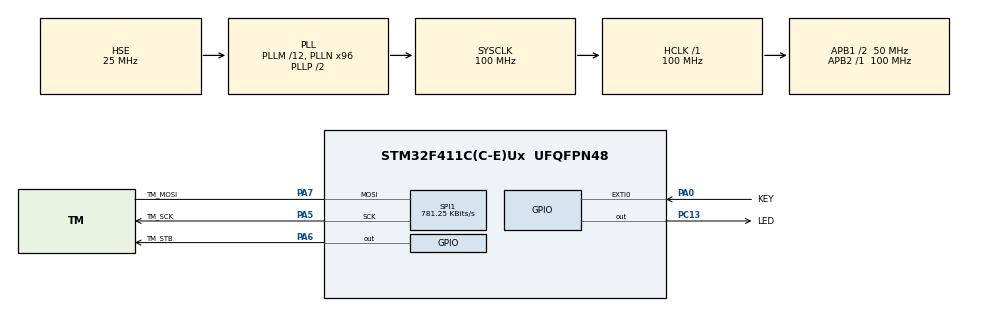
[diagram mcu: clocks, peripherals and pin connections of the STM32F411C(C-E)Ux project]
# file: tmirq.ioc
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Mcu.Family=STM32F4
Mcu.Name=STM32F411C(C-E)Ux
Mcu.Package=UFQFPN48
NVIC.EXTI0_IRQn=true\:0\:0\:false\:false\:true\:true\:true\:true
NVIC.PriorityGroup=NVIC_PRIORITYGROUP_4
NVIC.TIM1_BRK_TIM9_IRQn=true\:15\:0\:false\:false\:true\:false\:true\:true
NVIC.TimeBase=TIM1_BRK_TIM9_IRQn
NVIC.TimeBaseIP=TIM9
PA0-WKUP.GPIO_Label=KEY
PA0-WKUP.GPIO_ModeDefaultEXTI=GPIO_MODE_IT_RISING_FALLING
PA0-WKUP.GPIO_PuPd=GPIO_PULLUP
PA0-WKUP.Signal=GPXTI0
PA13.Mode=Serial_Wire
PA13.Signal=SYS_JTMS-SWDIO
PA14.Mode=Serial_Wire
PA14.Signal=SYS_JTCK-SWCLK
PA5.GPIO_Label=TM_SCK
PA5.Mode=Simplex_Bidirectional_Master
PA5.Signal=SPI1_SCK
PA6.GPIO_Label=TM_STB
PA6.GPIO_PuPd=GPIO_PULLUP
PA6.GPIO_Speed=GPIO_SPEED_FREQ_VERY_HIGH
PA6.PinState=GPIO_PIN_SET
PA6.Signal=GPIO_Output
PA7.GPIO_Label=TM_MOSI
PA7.Mode=Simplex_Bidirectional_Master
PA7.Signal=SPI1_MOSI
PC13-ANTI_TAMP.GPIO_Label=LED
PC13-ANTI_TAMP.GPIO_PuPd=GPIO_PULLUP
PC13-ANTI_TAMP.PinState=GPIO_PIN_SET
PC13-ANTI_TAMP.Signal=GPIO_Output
PH0\ -\ OSC_IN.Mode=HSE-External-Oscillator
PH0\ -\ OSC_IN.Signal=RCC_OSC_IN
PH1\ -\ OSC_OUT.Mode=HSE-External-Oscillator
PH1\ -\ OSC_OUT.Signal=RCC_OSC_OUT
ProjectManager.HeapSize=0x200
ProjectManager.StackSize=0x400
ProjectManager.TargetToolchain=STM32CubeIDE
RCC.48MHZClocksFreq_Value=50000000
RCC.AHBFreq_Value=100000000
RCC.APB1CLKDivider=RCC_HCLK_DIV2
RCC.APB1Freq_Value=50000000
RCC.APB1TimFreq_Value=100000000
RCC.APB2Freq_Value=100000000
RCC.APB2TimFreq_Value=100000000
RCC.CortexFreq_Value=100000000
RCC.HCLKFreq_Value=100000000
RCC.HSE_VALUE=25000000
RCC.HSI_VALUE=16000000
RCC.LSE_VALUE=32768
RCC.PLLM=12
RCC.PLLN=96
RCC.PLLSourceVirtual=RCC_PLLSOURCE_HSE
RCC.SYSCLKFreq_VALUE=100000000
RCC.SYSCLKSource=RCC_SYSCLKSOURCE_PLLCLK
RCC.VCOOutputFreq_Value=200000000
SPI1.BaudRatePrescaler=SPI_BAUDRATEPRESCALER_128
SPI1.CLKPhase=SPI_PHASE_2EDGE
SPI1.CLKPolarity=SPI_POLARITY_HIGH
SPI1.CalculateBaudRate=781.25 KBits/s
SPI1.Direction=SPI_DIRECTION_1LINE
SPI1.FirstBit=SPI_FIRSTBIT_LSB
SPI1.Mode=SPI_MODE_MASTER
SPI1.VirtualType=VM_MASTER
VP_SYS_VS_tim9.Mode=TIM9
board=custom

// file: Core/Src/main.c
/* USER CODE BEGIN Header */
/**
  ******************************************************************************
  * @file           : main.c
  * @brief          : Main program body
  ******************************************************************************
  * @attention
  *
  * Copyright (c) 2024 STMicroelectronics.
  * All rights reserved.
  *
  * This software is licensed under terms that can be found in the LICENSE file
  * in the root directory of this software component.
  * If no LICENSE file comes with this software, it is provided AS-IS.
  *
  ******************************************************************************
  */
/* USER CODE END Header */
#include "main.h"
#include "spi.h"
#include "gpio.h"

/* USER CODE BEGIN Includes */
#include "EventLoop.h"
/* USER CODE END Includes */

void SystemClock_Config(void);

int main(void)
{

  /* MCU Configuration--------------------------------------------------------*/

  /* Reset of all peripherals, Initializes the Flash interface and the Systick. */
  HAL_Init();

  /* Configure the system clock */
  SystemClock_Config();

  /* Initialize all configured peripherals */
  MX_GPIO_Init();
  MX_SPI1_Init();

  /* Infinite loop */
  /* USER CODE BEGIN WHILE */
  EventLoopC();

  while (1)
  {
    /* USER CODE END WHILE */

  }
}

void SystemClock_Config(void)
{
  RCC_OscInitTypeDef RCC_OscInitStruct = {0};
  RCC_ClkInitTypeDef RCC_ClkInitStruct = {0};

  /** Configure the main internal regulator output voltage
  */
  __HAL_RCC_PWR_CLK_ENABLE();
  __HAL_PWR_VOLTAGESCALING_CONFIG(PWR_REGULATOR_VOLTAGE_SCALE1);

  /** Initializes the RCC Oscillators according to the specified parameters
  * in the RCC_OscInitTypeDef structure.
  */
  RCC_OscInitStruct.OscillatorType = RCC_OSCILLATORTYPE_HSE;
  RCC_OscInitStruct.HSEState = RCC_HSE_ON;
  RCC_OscInitStruct.PLL.PLLState = RCC_PLL_ON;
  RCC_OscInitStruct.PLL.PLLSource = RCC_PLLSOURCE_HSE;
  RCC_OscInitStruct.PLL.PLLM = 12;
  RCC_OscInitStruct.PLL.PLLN = 96;
  RCC_OscInitStruct.PLL.PLLP = RCC_PLLP_DIV2;
  RCC_OscInitStruct.PLL.PLLQ = 4;
  if (HAL_RCC_OscConfig(&RCC_OscInitStruct) != HAL_OK)
  {
    Error_Handler();
  }

  /** Initializes the CPU, AHB and APB buses clocks
  */
  RCC_ClkInitStruct.ClockType = RCC_CLOCKTYPE_HCLK|RCC_CLOCKTYPE_SYSCLK
                              |RCC_CLOCKTYPE_PCLK1|RCC_CLOCKTYPE_PCLK2;
  RCC_ClkInitStruct.SYSCLKSource = RCC_SYSCLKSOURCE_PLLCLK;
  RCC_ClkInitStruct.AHBCLKDivider = RCC_SYSCLK_DIV1;
  RCC_ClkInitStruct.APB1CLKDivider = RCC_HCLK_DIV2;
  RCC_ClkInitStruct.APB2CLKDivider = RCC_HCLK_DIV1;

  if (HAL_RCC_ClockConfig(&RCC_ClkInitStruct, FLASH_LATENCY_3) != HAL_OK)
  {
    Error_Handler();
  }
}

void HAL_TIM_PeriodElapsedCallback(TIM_HandleTypeDef *htim)
{
  if (htim->Instance == TIM9) {
    HAL_IncTick();
  }
}

void Error_Handler(void)
{
  __disable_irq();
  while (1)
  {
  }
}
